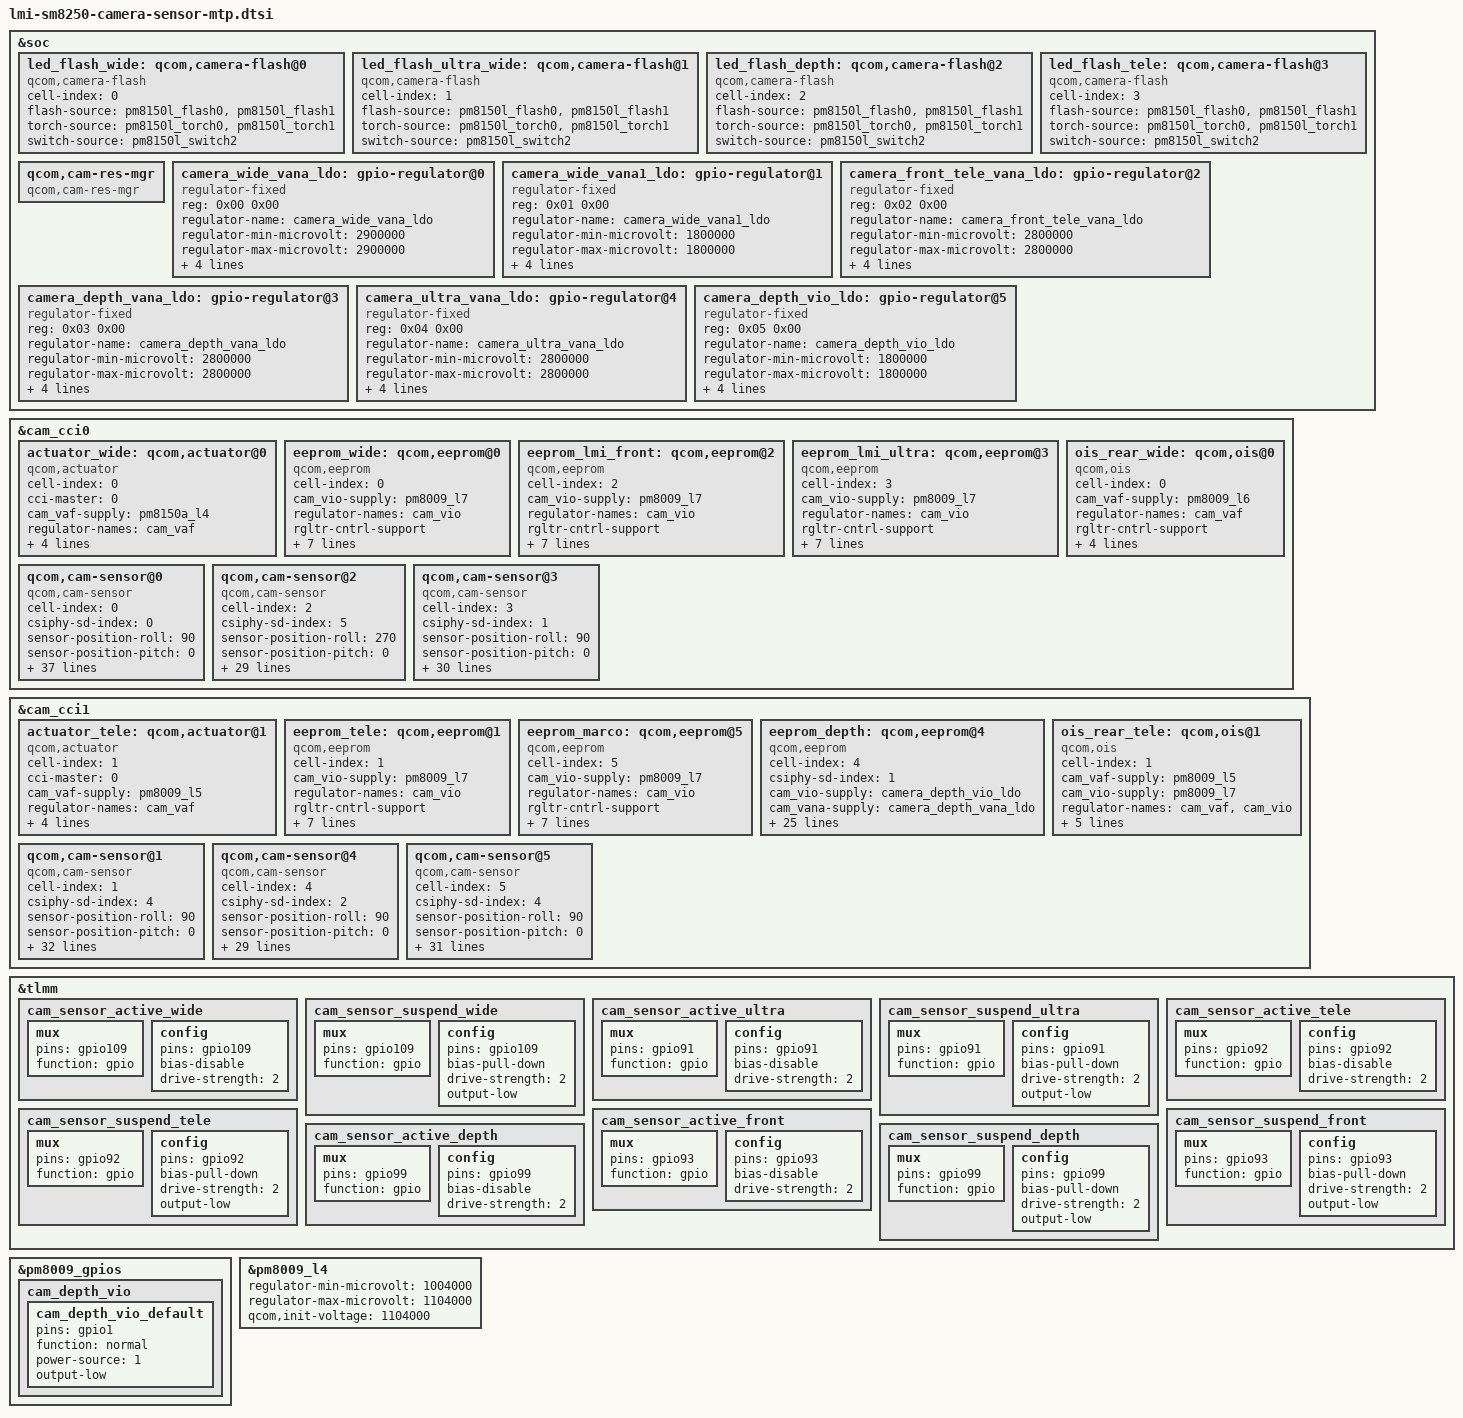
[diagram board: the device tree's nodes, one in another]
&soc {
	led_flash_wide: qcom,camera-flash@0 {
		cell-index = <0>;
		compatible = "qcom,camera-flash";
		flash-source = <&pm8150l_flash0 &pm8150l_flash1>;
		torch-source = <&pm8150l_torch0 &pm8150l_torch1>;
		switch-source = <&pm8150l_switch2>;
		status = "ok";
	};

	led_flash_ultra_wide: qcom,camera-flash@1 {
		cell-index = <1>;
		compatible = "qcom,camera-flash";
		flash-source = <&pm8150l_flash0 &pm8150l_flash1>;
		torch-source = <&pm8150l_torch0 &pm8150l_torch1>;
		switch-source = <&pm8150l_switch2>;
		status = "ok";
	};

	led_flash_depth: qcom,camera-flash@2 {
		cell-index = <2>;
		compatible = "qcom,camera-flash";
		flash-source = <&pm8150l_flash0 &pm8150l_flash1>;
		torch-source = <&pm8150l_torch0 &pm8150l_torch1>;
		switch-source = <&pm8150l_switch2>;
		status = "ok";
	};

	led_flash_tele: qcom,camera-flash@3 {
		cell-index = <3>;
		compatible = "qcom,camera-flash";
		flash-source = <&pm8150l_flash0 &pm8150l_flash1>;
		torch-source = <&pm8150l_torch0 &pm8150l_torch1>;
		switch-source = <&pm8150l_switch2>;
		status = "ok";
	};

	qcom,cam-res-mgr {
		compatible = "qcom,cam-res-mgr";
		status = "ok";
	};

	camera_wide_vana_ldo: gpio-regulator@0 {
			compatible = "regulator-fixed";
			reg = <0x00 0x00>;
			regulator-name = "camera_wide_vana_ldo";
			regulator-min-microvolt = <2900000>;
			regulator-max-microvolt = <2900000>;
			regulator-enable-ramp-delay = <135>;
			enable-active-high;
			gpio = <&tlmm 12 0>;
			vin-supply = <&pm8150a_bob>;
	};

	camera_wide_vana1_ldo: gpio-regulator@1 {
			compatible = "regulator-fixed";
			reg = <0x01 0x00>;
			regulator-name = "camera_wide_vana1_ldo";
			regulator-min-microvolt = <1800000>;
			regulator-max-microvolt = <1800000>;
			regulator-enable-ramp-delay = <135>;
			enable-active-high;
			gpio = <&tlmm 11 0>;
			vin-supply = <&pm8150a_bob>;
	};

	camera_front_tele_vana_ldo: gpio-regulator@2 {
		compatible = "regulator-fixed";
		reg = <0x02 0x00>;
		regulator-name = "camera_front_tele_vana_ldo";
		regulator-min-microvolt = <2800000>;
		regulator-max-microvolt = <2800000>;
		regulator-enable-ramp-delay = <135>;
		enable-active-high;
		gpio = <&tlmm 15 0>;
		vin-supply = <&pm8150a_bob>;
	};

	camera_depth_vana_ldo: gpio-regulator@3 {
		compatible = "regulator-fixed";
		reg = <0x03 0x00>;
		regulator-name = "camera_depth_vana_ldo";
		regulator-min-microvolt = <2800000>;
		regulator-max-microvolt = <2800000>;
		regulator-enable-ramp-delay = <135>;
		enable-active-high;
		gpio = <&tlmm 10 0>;
		vin-supply = <&pm8150a_bob>;
	};

	camera_ultra_vana_ldo: gpio-regulator@4 {
		compatible = "regulator-fixed";
		reg = <0x04 0x00>;
		regulator-name = "camera_ultra_vana_ldo";
		regulator-min-microvolt = <2800000>;
		regulator-max-microvolt = <2800000>;
		regulator-enable-ramp-delay = <135>;
		enable-active-high;
		gpio = <&tlmm 63 0>;
		vin-supply = <&pm8150a_bob>;
	};

	camera_depth_vio_ldo: gpio-regulator@5 {
		compatible = "regulator-fixed";
		reg = <0x05 0x00>;
		regulator-name = "camera_depth_vio_ldo";
		regulator-min-microvolt = <1800000>;
		regulator-max-microvolt = <1800000>;
		regulator-enable-ramp-delay = <135>;
		enable-active-high;
		gpio = <&pm8009_gpios 1 0>;
		vin-supply = <&pm8009_l7>;
	};
};

&cam_cci0 {
	/*  J11 Wide actuator */
	actuator_wide: qcom,actuator@0 {
		cell-index = <0>;
		compatible = "qcom,actuator";
		cci-master = <0>;
		cam_vaf-supply = <&pm8150a_l4>;
		regulator-names = "cam_vaf";
		rgltr-cntrl-support;
		rgltr-min-voltage = <2800000>;
		rgltr-max-voltage = <2800000>;
		rgltr-load-current = <100000>;
	};

	/*  J11 Wide eeprom */
	eeprom_wide: qcom,eeprom@0 {
		cell-index = <0>;
		compatible = "qcom,eeprom";
		cam_vio-supply = <&pm8009_l7>;
		regulator-names = "cam_vio";
		rgltr-cntrl-support;
		pwm-switch;
		rgltr-min-voltage = <1800000>;
		rgltr-max-voltage = <1800000>;
		rgltr-load-current = <120000>;
		gpio-no-mux = <0>;
		sensor-mode = <0>;
		cci-master = <0>;
		status = "ok";
	};

	/*  J11 Front eeprom */
	eeprom_lmi_front: qcom,eeprom@2 {
		cell-index = <2>;
		compatible = "qcom,eeprom";
		cam_vio-supply = <&pm8009_l7>;
		regulator-names = "cam_vio";
		rgltr-cntrl-support;
		pwm-switch;
		rgltr-min-voltage = <1800000>;
		rgltr-max-voltage = <1800000>;
		rgltr-load-current = <120000>;
		gpio-no-mux = <0>;
		sensor-mode = <0>;
		cci-master = <1>;
		status = "ok";
	};

	/*  J11 Ultra eeprom */
	eeprom_lmi_ultra: qcom,eeprom@3 {
		cell-index = <3>;
		compatible = "qcom,eeprom";
		cam_vio-supply = <&pm8009_l7>;
		regulator-names = "cam_vio";
		rgltr-cntrl-support;
		pwm-switch;
		rgltr-min-voltage = <1800000>;
		rgltr-max-voltage = <1800000>;
		rgltr-load-current = <120000>;
		gpio-no-mux = <0>;
		sensor-mode = <0>;
		cci-master = <1>;
		status = "ok";
	};

	/*  J11 Wide ois */
	ois_rear_wide: qcom,ois@0 {
		cell-index = <0>;
		compatible = "qcom,ois";
		cam_vaf-supply = <&pm8009_l6>;
		regulator-names = "cam_vaf";
		rgltr-cntrl-support;
		rgltr-min-voltage = <2850000>;
		rgltr-max-voltage = <2850000>;
		rgltr-load-current = <100000>;
		cci-master = <0>;
		status = "ok";
	};

	/*  J11 wide sensor */
	qcom,cam-sensor@0 {
		cell-index = <0>;
		compatible = "qcom,cam-sensor";
		csiphy-sd-index = <0>;
		sensor-position-roll = <90>;
		sensor-position-pitch = <0>;
		sensor-position-yaw = <180>;
		eeprom-src = <&eeprom_wide>;
		led-flash-src = <&led_flash_wide>;
		actuator-src = <&actuator_wide>;
		ois-src = <&ois_rear_wide>;
		cam_vio-supply = <&pm8009_l7>;
		cam_vana-supply = <&camera_wide_vana_ldo>;
		cam_vaf-supply = <&pm8009_l6>;
		cam_v_custom1-supply = <&camera_wide_vana1_ldo>;
		cam_vdig-supply = <&pm8009_l1>;
		cam_clk-supply = <&titan_top_gdsc>;
		regulator-names = "cam_vio", "cam_vana","cam_vaf","cam_v_custom1","cam_vdig", "cam_clk";
		rgltr-cntrl-support;
		pwm-switch;
		rgltr-min-voltage = <1800000 2900000 2850000 1800000 1104000 0>;
		rgltr-max-voltage = <1800000 2900000 2850000 1800000 1104000 0>;
		rgltr-load-current = <120000 80000 100000 180000 1200000 0>;
		gpio-no-mux = <0>;
		pinctrl-names = "cam_default", "cam_suspend";
		pinctrl-0 = <&cam_sensor_mclk0_active
				&cam_sensor_active_wide>;
		pinctrl-1 = <&cam_sensor_mclk0_suspend
				&cam_sensor_suspend_wide>;
		gpios = <&tlmm 94 0>,
			<&tlmm 109 0>;
		gpio-reset = <1>;
		gpio-req-tbl-num = <0 1>;
		gpio-req-tbl-flags = <1 0>;
		gpio-req-tbl-label = "CAMIF_MCLK_WIDE",
					"CAM_RESET_WIDE";
		sensor-mode = <0>;
		cci-master = <0>;
		status = "ok";
		clocks = <&clock_camcc CAM_CC_MCLK0_CLK>;
		clock-names = "cam_clk";
		clock-cntl-level = "turbo";
		clock-rates = <19200000>;
	};

	/*  J11 Front sensor */
	qcom,cam-sensor@2 {
		cell-index = <2>;
		compatible = "qcom,cam-sensor";
		csiphy-sd-index = <5>;
		sensor-position-roll = <270>;
		sensor-position-pitch = <0>;
		sensor-position-yaw = <0>;
		eeprom-src = <&eeprom_lmi_front>;
		cam_vio-supply = <&pm8009_l7>;
		cam_vana-supply = <&camera_front_tele_vana_ldo>;
		cam_vdig-supply = <&pm8009_l4>;
		cam_clk-supply = <&titan_top_gdsc>;
		regulator-names = "cam_vio", "cam_vana", "cam_vdig",
			"cam_clk";
		rgltr-cntrl-support;
		pwm-switch;
		rgltr-min-voltage = <1800000 2800000 1070000 0>;
		rgltr-max-voltage = <1800000 2800000 1070000 0>;
		rgltr-load-current = <120000 80000 1200000 0>;
		gpio-no-mux = <0>;
		pinctrl-names = "cam_default", "cam_suspend";
		pinctrl-0 = <&cam_sensor_mclk3_active
				 &cam_sensor_active_front>;
		pinctrl-1 = <&cam_sensor_mclk3_suspend
				 &cam_sensor_suspend_front>;
		gpios = <&tlmm 97 0>,
			<&tlmm 93 0>;
		gpio-reset = <1>;
		gpio-req-tbl-num = <0 1>;
		gpio-req-tbl-flags = <1 0>;
		gpio-req-tbl-label = "CAMIF_MCLK_FRONT",
					"CAM_RESET_FRONT";
		sensor-mode = <0>;
		cci-master = <1>;
		status = "ok";
		clocks = <&clock_camcc CAM_CC_MCLK3_CLK>;
		clock-names = "cam_clk";
		clock-cntl-level = "turbo";
		clock-rates = <19200000>;
	};

	/*  J11 Ultra Wide sensor */
	qcom,cam-sensor@3 {
		cell-index = <3>;
		compatible = "qcom,cam-sensor";
		csiphy-sd-index = <1>;
		sensor-position-roll = <90>;
		sensor-position-pitch = <0>;
		sensor-position-yaw = <180>;
		eeprom-src = <&eeprom_lmi_ultra>;
		led-flash-src = <&led_flash_ultra_wide>;
		cam_vana-supply = <&camera_ultra_vana_ldo>;
		cam_vio-supply = <&pm8009_l7>;
		cam_vdig-supply = <&pm8009_l3>;
		cam_clk-supply = <&titan_top_gdsc>;
		regulator-names = "cam_vio", "cam_vdig",
			"cam_clk","cam_vana";
		rgltr-cntrl-support;
		pwm-switch;
		rgltr-min-voltage = <1800000 1200000 0 2800000>;
		rgltr-max-voltage = <1800000 1200000 0 2800000>;
		rgltr-load-current = <120000 1056000 0 80000>;
		gpio-no-mux = <0>;
		pinctrl-names = "cam_default", "cam_suspend";
		pinctrl-0 = <&cam_sensor_mclk2_active
			     &cam_sensor_active_ultra>;
		pinctrl-1 = <&cam_sensor_mclk2_suspend
			     &cam_sensor_active_ultra>;
		gpios = <&tlmm 96 0>,
			<&tlmm 91 0>;
		gpio-reset = <1>;
		gpio-req-tbl-num = <0 1>;
		gpio-req-tbl-flags = <1 0>;
		gpio-req-tbl-label = "CAMIF_MCLK_ULTRA",
					"CAM_RESET_ULTRA";
		sensor-mode = <0>;
		cci-master = <1>;
		status = "ok";
		clocks = <&clock_camcc CAM_CC_MCLK2_CLK>;
		clock-names = "cam_clk";
		clock-cntl-level = "turbo";
		clock-rates = <19200000>;
	};
};

&cam_cci1 {
	/*  J11 Macro actuator */
	actuator_tele: qcom,actuator@1 {
		cell-index = <1>;
		compatible = "qcom,actuator";
		cci-master = <0>;
		cam_vaf-supply = <&pm8009_l5>;
		regulator-names = "cam_vaf";
		rgltr-cntrl-support;
		rgltr-min-voltage = <2850000>;
		rgltr-max-voltage = <2850000>;
		rgltr-load-current = <100000>;
	};

	/*  J11 Tele/Macro eeprom */
	eeprom_tele: qcom,eeprom@1 {
		cell-index = <1>;
		compatible = "qcom,eeprom";
		cam_vio-supply = <&pm8009_l7>;
		regulator-names = "cam_vio";
		rgltr-cntrl-support;
		pwm-switch;
		rgltr-min-voltage = <1800000>;
		rgltr-max-voltage = <1800000>;
		rgltr-load-current = <120000>;
		gpio-no-mux = <0>;
		sensor-mode = <0>;
		cci-master = <0>;
		status = "ok";
	};

	eeprom_marco: qcom,eeprom@5 {
		cell-index = <5>;
		compatible = "qcom,eeprom";
		cam_vio-supply = <&pm8009_l7>;
		regulator-names = "cam_vio";
		rgltr-cntrl-support;
		pwm-switch;
		rgltr-min-voltage = <1800000>;
		rgltr-max-voltage = <1800000>;
		rgltr-load-current = <120000>;
		gpio-no-mux = <0>;
		sensor-mode = <0>;
		cci-master = <0>;
		status = "ok";
	};

	eeprom_depth: qcom,eeprom@4 {
		cell-index = <4>;
		compatible = "qcom,eeprom";
		csiphy-sd-index = <1>;
		cam_vio-supply = <&camera_depth_vio_ldo>;
		cam_vana-supply = <&camera_depth_vana_ldo>;
		cam_clk-supply = <&titan_top_gdsc>;
		regulator-names = "cam_vio", "cam_vana",
			"cam_clk";
		rgltr-cntrl-support;
		pwm-switch;
		rgltr-min-voltage = <1800000 2800000 0>;
		rgltr-max-voltage = <1800000 2800000 0>;
		rgltr-load-current = <120000 80000 0>;
		gpio-no-mux = <0>;
		pinctrl-names = "cam_default", "cam_suspend";
		pinctrl-0 = <&cam_sensor_mclk1_active
				&cam_sensor_active_depth
				&cam_depth_vio_default>;
		pinctrl-1 = <&cam_sensor_mclk1_suspend
				&cam_sensor_suspend_depth
				&cam_depth_vio_default>;
		gpios = <&tlmm 95 0>,
			<&tlmm 99 0>;
		gpio-reset = <1>;
		gpio-req-tbl-num = <0 1>;
		gpio-req-tbl-flags = <1 0>;
		gpio-req-tbl-label = "CAMIF_MCLK_DEPTH",
					"CAM_RESET_DEPTH";
		sensor-mode = <0>;
		cci-master = <1>;
		status = "ok";
		clocks = <&clock_camcc CAM_CC_MCLK1_CLK>;
		clock-names = "cam_clk";
		clock-cntl-level = "turbo";
		clock-rates = <19200000>;
	};

	/*  J11 Tele/Macro ois */
	ois_rear_tele: qcom,ois@1 {
		cell-index = <1>;
		compatible = "qcom,ois";
		cam_vaf-supply = <&pm8009_l5>;
		cam_vio-supply = <&pm8009_l7>;
		regulator-names = "cam_vaf","cam_vio";
		rgltr-cntrl-support;
		rgltr-min-voltage = <2850000 1800000>;
		rgltr-max-voltage = <2850000 1800000>;
		rgltr-load-current = <100000 120000>;
		cci-master = <0>;
		status = "ok";
	};

	/*  J11 Tele sensor */
	qcom,cam-sensor@1 {
		cell-index = <1>;
		compatible = "qcom,cam-sensor";
		csiphy-sd-index = <4>;
		sensor-position-roll = <90>;
		sensor-position-pitch = <0>;
		sensor-position-yaw = <180>;
		actuator-src = <&actuator_tele>;
		ois-src = <&ois_rear_tele>;
		led-flash-src = <&led_flash_tele>;
		eeprom-src = <&eeprom_tele>;
		cam_vio-supply = <&pm8009_l7>;
		cam_vana-supply = <&camera_front_tele_vana_ldo>;
		cam_vdig-supply = <&pm8009_l2>;
		cam_clk-supply = <&titan_top_gdsc>;
		regulator-names = "cam_vio", "cam_vana", "cam_vdig",
			"cam_clk";
		rgltr-cntrl-support;
		pwm-switch;
		rgltr-min-voltage = <1800000 2800000 1200000 0>;
		rgltr-max-voltage = <1800000 2800000 1200000 0>;
		rgltr-load-current = <120000 80000 1200000 0>;
		gpio-no-mux = <0>;
		pinctrl-names = "cam_default", "cam_suspend";
		pinctrl-0 = <&cam_sensor_mclk4_active
				&cam_sensor_active_tele>;
		pinctrl-1 = <&cam_sensor_mclk4_suspend
				&cam_sensor_suspend_tele>;
		gpios = <&tlmm 98 0>,
			<&tlmm 92 0>;
		gpio-reset = <1>;
		gpio-req-tbl-num = <0 1>;
		gpio-req-tbl-flags = <1 0>;
		gpio-req-tbl-label = "CAMIF_MCLK_TELE",
					"CAM_RESET_TELE";
		sensor-mode = <0>;
		cci-master = <0>;
		status = "ok";
		clocks = <&clock_camcc CAM_CC_MCLK4_CLK>;
		clock-names = "cam_clk";
		clock-cntl-level = "turbo";
		clock-rates = <19200000>;
	};

	/*  J11 Depth sensor */
	qcom,cam-sensor@4 {
		cell-index = <4>;
		compatible = "qcom,cam-sensor";
		csiphy-sd-index = <2>;
		sensor-position-roll = <90>;
		sensor-position-pitch = <0>;
		sensor-position-yaw = <180>;
		//led-flash-src = <&led_flash_depth>;
		eeprom-src = <&eeprom_depth>;
		cam_vio-supply = <&camera_depth_vio_ldo>;
		cam_vana-supply = <&camera_depth_vana_ldo>;
		cam_clk-supply = <&titan_top_gdsc>;
		regulator-names = "cam_vio", "cam_vana",
			"cam_clk";
		rgltr-cntrl-support;
		pwm-switch;
		rgltr-min-voltage = <1800000 2800000 0>;
		rgltr-max-voltage = <1800000 2800000 0>;
		rgltr-load-current = <120000 80000 0>;
		gpio-no-mux = <0>;
		pinctrl-names = "cam_default", "cam_suspend";
		pinctrl-0 = <&cam_sensor_mclk1_active
				&cam_sensor_active_depth
				&cam_depth_vio_default>;
		pinctrl-1 = <&cam_sensor_mclk1_suspend
				&cam_sensor_suspend_depth
				&cam_depth_vio_default>;
		gpios = <&tlmm 95 0>,
			<&tlmm 99 0>;
		gpio-reset = <1>;
		gpio-req-tbl-num = <0 1>;
		gpio-req-tbl-flags = <1 0>;
		gpio-req-tbl-label = "CAMIF_MCLK_DEPTH",
					"CAM_RESET_DEPTH";
		sensor-mode = <0>;
		cci-master = <1>;
		status = "ok";
		clocks = <&clock_camcc CAM_CC_MCLK1_CLK>;
		clock-names = "cam_clk";
		clock-cntl-level = "turbo";
		clock-rates = <19200000>;
	};

	/*  J11 Macro sensor */
	qcom,cam-sensor@5 {
		cell-index = <5>;
		compatible = "qcom,cam-sensor";
		csiphy-sd-index = <4>;
		sensor-position-roll = <90>;
		sensor-position-pitch = <0>;
		sensor-position-yaw = <180>;
		actuator-src = <&actuator_tele>;
		led-flash-src = <&led_flash_tele>;
		eeprom-src = <&eeprom_marco>;
		cam_vio-supply = <&pm8009_l7>;
		cam_vana-supply = <&camera_front_tele_vana_ldo>;
		cam_vdig-supply = <&pm8009_l2>;
		cam_clk-supply = <&titan_top_gdsc>;
		regulator-names = "cam_vio", "cam_vana", "cam_vdig",
			"cam_clk";
		rgltr-cntrl-support;
		pwm-switch;
		rgltr-min-voltage = <1800000 2800000 1200000 0>;
		rgltr-max-voltage = <1800000 2800000 1200000 0>;
		rgltr-load-current = <120000 80000 1200000 0>;
		gpio-no-mux = <0>;
		pinctrl-names = "cam_default", "cam_suspend";
		pinctrl-0 = <&cam_sensor_mclk4_active
				&cam_sensor_active_tele>;
		pinctrl-1 = <&cam_sensor_mclk4_suspend
				&cam_sensor_suspend_tele>;
		gpios = <&tlmm 98 0>,
			<&tlmm 92 0>;
		gpio-reset = <1>;
		gpio-req-tbl-num = <0 1>;
		gpio-req-tbl-flags = <1 0>;
		gpio-req-tbl-label = "CAMIF_MCLK_MACRO",
					"CAM_RESET_MACRO";
		sensor-mode = <0>;
		cci-master = <0>;
		status = "ok";
		clocks = <&clock_camcc CAM_CC_MCLK4_CLK>;
		clock-names = "cam_clk";
		clock-cntl-level = "turbo";
		clock-rates = <19200000>;
	};
};

&tlmm {
	cam_sensor_active_wide: cam_sensor_active_wide {
		/* RESET WIDE */
		mux {
			pins = "gpio109";
			function = "gpio";
		};

		config {
			pins = "gpio109";
			bias-disable; /* No PULL */
			drive-strength = <2>; /* 2 MA */
		};
	};

	cam_sensor_suspend_wide: cam_sensor_suspend_wide {
		/* RESET WIDE */
		mux {
			pins = "gpio109";
			function = "gpio";
		};

		config {
			pins = "gpio109";
			bias-pull-down; /* PULL DOWN */
			drive-strength = <2>; /* 2 MA */
			output-low;
		};
	};

	cam_sensor_active_ultra: cam_sensor_active_ultra {
		/* RESET ULTRA */
		mux {
			pins = "gpio91";
			function = "gpio";
		};

		config {
			pins = "gpio91";
			bias-disable; /* No PULL */
			drive-strength = <2>; /* 2 MA */
		};
	};

	cam_sensor_suspend_ultra: cam_sensor_suspend_ultra {
		/* RESET ULTRA */
		mux {
			pins = "gpio91";
			function = "gpio";
		};

		config {
			pins = "gpio91";
			bias-pull-down; /* PULL DOWN */
			drive-strength = <2>; /* 2 MA */
			output-low;
		};
	};

	cam_sensor_active_tele: cam_sensor_active_tele {
		/* RESET TELE/MACRO */
		mux {
			pins = "gpio92";
			function = "gpio";
		};

		config {
			pins = "gpio92";
			bias-disable; /* No PULL */
			drive-strength = <2>; /* 2 MA */
		};
	};

	cam_sensor_suspend_tele: cam_sensor_suspend_tele {
		/* RESET TELE/MACRO */
		mux {
			pins = "gpio92";
			function = "gpio";
		};

		config {
			pins = "gpio92";
			bias-pull-down; /* PULL DOWN */
			drive-strength = <2>; /* 2 MA */
			output-low;
		};
	};

	cam_sensor_active_front: cam_sensor_active_front {
		/* RESET FRONT */
		mux {
			pins = "gpio93";
			function = "gpio";
		};

		config {
			pins = "gpio93";
			bias-disable; /* No PULL */
			drive-strength = <2>; /* 2 MA */
		};
	};

	cam_sensor_suspend_front: cam_sensor_suspend_front {
		/* RESET FRONT */
		mux {
			pins = "gpio93";
			function = "gpio";
		};

		config {
			pins = "gpio93";
			bias-pull-down; /* PULL DOWN */
			drive-strength = <2>; /* 2 MA */
			output-low;
		};
	};

	cam_sensor_active_depth: cam_sensor_active_depth {
		/* RESET DEPTH */
		mux {
			pins = "gpio99";
			function = "gpio";
		};

		config {
			pins = "gpio99";
			bias-disable; /* No PULL */
			drive-strength = <2>; /* 2 MA */
		};
	};

	cam_sensor_suspend_depth: cam_sensor_suspend_depth {
		/* RESET DEPTH */
		mux {
			pins = "gpio99";
			function = "gpio";
		};

		config {
			pins = "gpio99";
			bias-pull-down; /* PULL DOWN */
			drive-strength = <2>; /* 2 MA */
			output-low;
		};
	};
};

&pm8009_gpios {
	cam_depth_vio {
		cam_depth_vio_default: cam_depth_vio_default {
			pins = "gpio1";
			function = "normal";
			power-source = <1>;
			output-low;
		};
	};
};

&pm8009_l4 {
	regulator-min-microvolt = <1004000>;
	regulator-max-microvolt = <1104000>;
	qcom,init-voltage = <1104000>;
};
